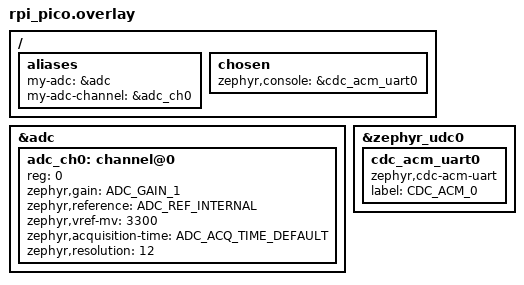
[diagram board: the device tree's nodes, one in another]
/ {
    aliases {
        
        my-adc = &adc;
        my-adc-channel = &adc_ch0;
    };

	chosen {
        zephyr,console = &cdc_acm_uart0;
    };
};

&adc {
    status = "okay";
    #address-cells = <1>;
    #size-cells = <0>;

    adc_ch0: channel@0 {
        reg = <0>;
        zephyr,gain = "ADC_GAIN_1";
        zephyr,reference = "ADC_REF_INTERNAL";
        zephyr,vref-mv = <3300>;
        zephyr,acquisition-time = <ADC_ACQ_TIME_DEFAULT>;
        zephyr,resolution = <12>;
    };
};

&zephyr_udc0 {
    cdc_acm_uart0: cdc_acm_uart0 {
        compatible = "zephyr,cdc-acm-uart";
        label = "CDC_ACM_0";
    };
};
